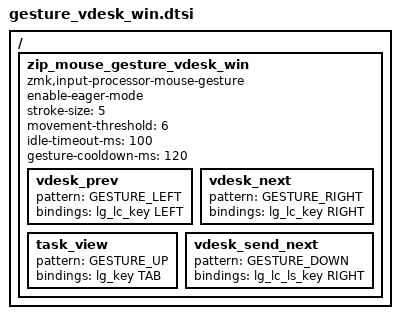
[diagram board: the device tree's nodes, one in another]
/ {
  zip_mouse_gesture_vdesk_win: zip_mouse_gesture_vdesk_win {
    compatible = "zmk,input-processor-mouse-gesture";
    #input-processor-cells = <0>;  
    enable-eager-mode;
    stroke-size = <5>;
    movement-threshold = <6>;
    idle-timeout-ms = <100>;
    gesture-cooldown-ms = <120>;

    vdesk_prev       { pattern = <GESTURE_LEFT>;  bindings = <&lg_lc_key LEFT>;      };
    vdesk_next       { pattern = <GESTURE_RIGHT>; bindings = <&lg_lc_key RIGHT>;     };
    task_view        { pattern = <GESTURE_UP>;    bindings = <&lg_key TAB>;          };
    vdesk_send_next  { pattern = <GESTURE_DOWN>;  bindings = <&lg_lc_ls_key RIGHT>;  };
  };
};
